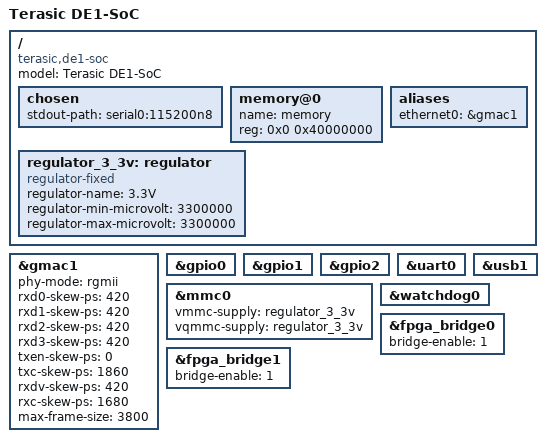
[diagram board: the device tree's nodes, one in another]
// SPDX-License-Identifier: GPL-2.0
/*
 * Terasic DE1-SoC (Cyclone V SoC, 5CSEMA5F31C6)
 *
 * Ported to mainline for the VUKA DE1-SoC image build. HPS peripherals follow
 * the DE0-Nano-SoC (same SoC family); board specifics (1 GB DDR3, gmac1 RGMII
 * skews) come from Terasic / U-Boot DE1-SoC support. The FPGA fabric (GHRD /
 * soc_system.rbf, loaded by U-Boot) is reached through the FPGA manager, bridges
 * and base FPGA region already defined in socfpga.dtsi; runtime reconfiguration
 * uses the configfs device-tree-overlay flow.
 */
/dts-v1/;
#include "socfpga_cyclone5.dtsi"

/ {
	model = "Terasic DE1-SoC";
	compatible = "terasic,de1-soc", "altr,socfpga-cyclone5", "altr,socfpga";

	chosen {
		stdout-path = "serial0:115200n8";
	};

	memory@0 {
		name = "memory";
		device_type = "memory";
		reg = <0x0 0x40000000>; /* 1 GB */
	};

	aliases {
		ethernet0 = &gmac1;
	};

	regulator_3_3v: regulator {
		compatible = "regulator-fixed";
		regulator-name = "3.3V";
		regulator-min-microvolt = <3300000>;
		regulator-max-microvolt = <3300000>;
	};
};

&gmac1 {
	status = "okay";
	phy-mode = "rgmii";

	rxd0-skew-ps = <420>;
	rxd1-skew-ps = <420>;
	rxd2-skew-ps = <420>;
	rxd3-skew-ps = <420>;
	txen-skew-ps = <0>;
	txc-skew-ps = <1860>;
	rxdv-skew-ps = <420>;
	rxc-skew-ps = <1680>;

	max-frame-size = <3800>;
};

&gpio0 {
	status = "okay";
};

&gpio1 {
	status = "okay";
};

&gpio2 {
	status = "okay";
};

&mmc0 {
	vmmc-supply = <&regulator_3_3v>;
	vqmmc-supply = <&regulator_3_3v>;
	status = "okay";
};

&uart0 {
	status = "okay";
};

&usb1 {
	status = "okay";
};

&watchdog0 {
	status = "okay";
};

/* HPS-to-FPGA bridges. Enabling them lets HPS software reach memory-mapped
 * slaves in the FPGA fabric (e.g. the camstream peripherals on the LW and
 * full H2F windows at 0xFF200000 / 0xC0000000). `bridge-enable = <1>` makes
 * the altera-fpga-bridge driver bring each bridge out of reset AND set the
 * L3 remap (via the l3regs syscon) at probe — the correct, in-kernel way to
 * route the windows. Doing this from userspace /dev/mem hangs the SoC (the
 * write-only L3 remap register is not safely writable that way), and enabling
 * in U-Boot does not survive kernel init, so it must be done here.
 * fpga_bridge0 = lwhps2fpga, fpga_bridge1 = hps2fpga. */
&fpga_bridge0 {
	status = "okay";
	bridge-enable = <1>;
};

&fpga_bridge1 {
	status = "okay";
	bridge-enable = <1>;
};

/* Note: fpgamgr0 and base_fpga_region are enabled by default in socfpga.dtsi,
 * so the GHRD fabric is reconfigurable at runtime via configfs DT overlays. */
